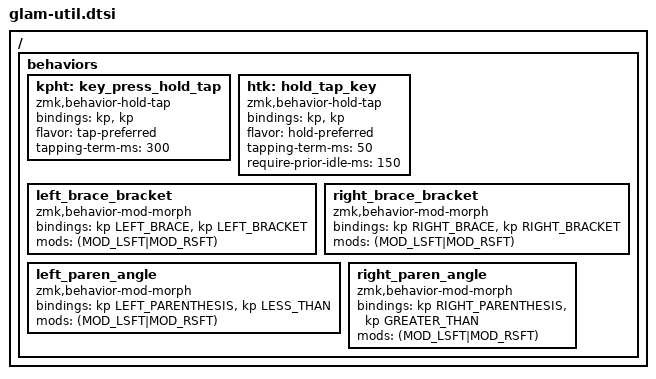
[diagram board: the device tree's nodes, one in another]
/*
 * Copyright (c) 2024 Allister MacLeod
 *
 * SPDX-License-Identifier: MIT
 */

// Devicetree include for sharing miscellaneous utility code between
// my various ZMK keymaps. Other .dtsi files in this directory have
// more specific themes:
//  - glam-bt-kbdctl.dtsi contains macros for dealing with Bluetooth
//  - glam-multigraph.dtsi is about character-sequence macros
//  - various glam-*-combos.dtsi files contain combos of different varieties

/ {

behaviors {
  // Hold-tap for two plain keycodes: hold param first, tap param second.
  kpht: key_press_hold_tap {
    compatible = "zmk,behavior-hold-tap";
    #binding-cells = <2>;
    bindings = <&kp>, <&kp>;
    flavor = "tap-preferred";
    tapping-term-ms = <300>;
  };
  // Hold-preferred hold-tap: tap does nothing, hold activates after a
  // deliberate press. Intended for keys where accidental taps should
  // be inert but intentional holds should fire.
  htk: hold_tap_key {
    compatible = "zmk,behavior-hold-tap";
    #binding-cells = <2>;
    bindings = <&kp>, <&kp>;
    flavor = "hold-preferred";
    tapping-term-ms = <50>;
    require-prior-idle-ms = <150>;
  };
  // Morph to reverse the shiftedness of left bracket and brace.
  left_brace_bracket: left_brace_bracket {
    compatible = "zmk,behavior-mod-morph";
    #binding-cells = <0>;
    bindings = <&kp LEFT_BRACE>, <&kp LEFT_BRACKET>;
    mods = <(MOD_LSFT|MOD_RSFT)>;
  };
  // Morph to reverse shiftedness of right bracket and brace.
  right_brace_bracket: right_brace_bracket {
    compatible = "zmk,behavior-mod-morph";
    #binding-cells = <0>;
    bindings = <&kp RIGHT_BRACE>, <&kp RIGHT_BRACKET>;
    mods = <(MOD_LSFT|MOD_RSFT)>;
  };
  // Morph for left parenthesis and left angle bracket.
  left_paren_angle: left_paren_angle {
    compatible = "zmk,behavior-mod-morph";
    #binding-cells = <0>;
    bindings = <&kp LEFT_PARENTHESIS>, <&kp LESS_THAN>;
    mods = <(MOD_LSFT|MOD_RSFT)>;
  };
  // Morph for right parenthesis and right angle bracket.
  right_paren_angle: right_paren_angle {
    compatible = "zmk,behavior-mod-morph";
    #binding-cells = <0>;
    bindings = <&kp RIGHT_PARENTHESIS>, <&kp GREATER_THAN>;
    mods = <(MOD_LSFT|MOD_RSFT)>;
  };
};

};
